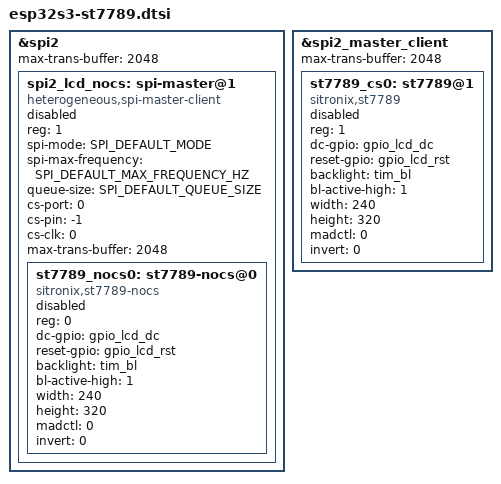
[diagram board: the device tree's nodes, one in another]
// SPDX-License-Identifier: Apache-2.0
/*
 * ESP32-S3 ST7789 LCD — DC/RST → vfs-gpio；背光 → vfs-tim
 */

#include <dt-bindings/spi/spi-parameter.h>

&spi2 {
	max-trans-buffer = <2048>;

	spi2_lcd_nocs: spi-master@1 {
		compatible = "heterogeneous,spi-master-client";
		reg = <1>;
		#address-cells = <1>;
		#size-cells = <0>;
		spi-mode = <SPI_DEFAULT_MODE>;
		spi-max-frequency = <SPI_DEFAULT_MAX_FREQUENCY_HZ>;
		queue-size = <SPI_DEFAULT_QUEUE_SIZE>;
		cs-port = <0>;
		cs-pin  = <-1>;
		cs-clk  = <0>;
		max-trans-buffer = <2048>;
		status = "disabled";

		st7789_nocs0: st7789-nocs@0 {
			compatible = "sitronix,st7789-nocs";
			reg = <0>;
			dc-gpio = <&gpio_lcd_dc>;
			reset-gpio = <&gpio_lcd_rst>;
			backlight = <&tim_bl>;
			bl-active-high = <1>;
			width = <240>;
			height = <320>;
			madctl = <0>;
			invert = <0>;
			status = "disabled";
		};
	};
};

&spi2_master_client {
	max-trans-buffer = <2048>;

	st7789_cs0: st7789@1 {
		compatible = "sitronix,st7789";
		reg = <1>;
		dc-gpio = <&gpio_lcd_dc>;
		reset-gpio = <&gpio_lcd_rst>;
		backlight = <&tim_bl>;
		bl-active-high = <1>;
		width = <240>;
		height = <320>;
		madctl = <0>;
		invert = <0>;
		status = "disabled";
	};
};
